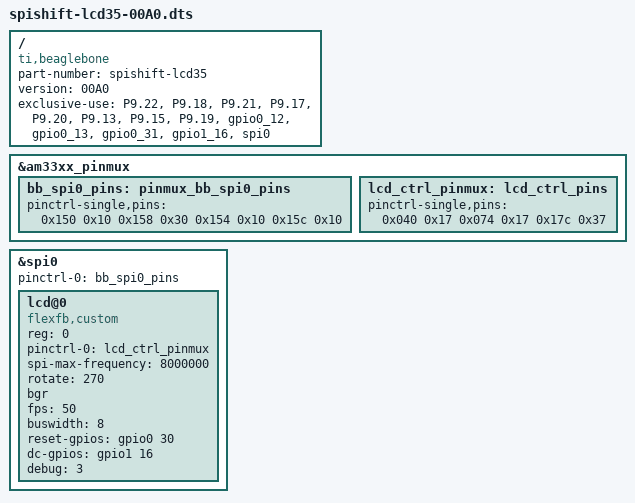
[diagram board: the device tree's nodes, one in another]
/*
 * Based on NEOSEC-TINYLCD35-00A0.dts, which is:
 * Copyright (C) 2014 Noralf Tronnes
 *
 * spishift-lcd35 : 4 wire SPI->shift register 3.5" display, on SPI0
 *
 * This program is free software; you can redistribute it and/or modify
 * it under the terms of the GNU General Public License version 2 as
 * published by the Free Software Foundation.
 */

/dts-v1/;
/plugin/;
/ {
	compatible = "ti,beaglebone", "ti,beaglebone-black";

	/* identification */
	part-number = "spishift-lcd35";
	version = "00A0";

	/* state the resources this cape uses */
	exclusive-use =
		/* the pin header uses */
		"P9.22",	/* spi0_sclk */
		"P9.18",	/* spi0_d1 MISO note we are using ti,pindir-d0-out-d1-in = <1> in spi0 */
		"P9.21",	/* spi0_d0 MOSI note we are using ti,pindir-d0-out-d1-in = <1> in spi0 */
		"P9.17",	/* spi0_cs0 */
		"P9.20",	/* gpio0_12 (12) second cs for touch */
		"P9.13",	/* gpio0_31 (31) display reset */
		"P9.15",	/* gpio1_16 (48) display dc data/command */
		"P9.19",	/* gpio0_13 (13) touch irq */
		/* the hardware IP uses */
		"gpio0_12",
		"gpio0_13",
		"gpio0_31",
		"gpio1_16",
		"spi0";

	fragment@0 {
		target = <&am33xx_pinmux>;
		__overlay__ {
			bb_spi0_pins: pinmux_bb_spi0_pins {
				pinctrl-single,pins = <
				        0x150 0x10      /* (PIN_OUTPUT_PULLUP | MUX_MODE0) spi0_sclk */
					0x158 0x30      /* (PIN_INPUT_PULLUP | MUX_MODE0)  spi0_d1 (input) */
					0x154 0x10      /* (PIN_OUTPUT_PULLUP | MUX_MODE0) spi0_d0 (output) */
					0x15c 0x10      /* (PIN_OUTPUT_PULLUP | MUX_MODE0) spi0_cs0 */
				>;
			};

			lcd_ctrl_pinmux: lcd_ctrl_pins {
				pinctrl-single,pins = <
					0x040 0x17	/* P9.15 gpio1_16  OUTPUT_PULLUP | MODE7 (DSP_DC) */
					0x074 0x17	/* P9.13 gpio0_30  OUTPUT_PULLUP | MODE7 (DSP_RESET) */
					0x17c 0x37	/* P9.19 gpio0_13  INPUT_PULLUP  | MODE7 (TP_IRQ) */
				>;
			};
		};
	};

	fragment@1 {
		target = <&spi0>;
		__overlay__ {
			status = "okay";
			pinctrl-names = "default";
			pinctrl-0 = <&bb_spi0_pins>;

			#address-cells = <1>;
			#size-cells = <0>;

			lcd@0{
				compatible = "flexfb,custom";
				reg = <0>;

				pinctrl-names = "default";
				pinctrl-0 = <&lcd_ctrl_pinmux>;

//				spi-max-frequency = <48000000>;
				spi-max-frequency = <8000000>;
				rotate = <270>;
				bgr;
				fps = <50>;
				buswidth = <8>;
				reset-gpios = <&gpio0 30 0>;
				dc-gpios = <&gpio1 16 0>;

				debug = <3>;
			};
		};
	};

	// fragment@2 {
	// 	target = <&epwmss1>;
	// 	__overlay__ {
	// 		status = "okay";
	// 	};
	// };

	// fragment@3 {
	// 	target = <&ehrpwm1>;
	// 	__overlay__ {
	// 		status = "okay";
	// 	};
	// };

	// fragment@4 {
	// 	target = <&ocp>;
	// 	__overlay__ {
	// 		backlight {
	// 			compatible = "pwm-backlight";
	// 			pinctrl-names = "default";
	// 			pinctrl-0 = <&pwm_bl_pins>;
	// 			status = "okay";

	// 			pwms = <&ehrpwm1 0 500000 0>;
	// 			pwm-names = "backlight";
	// 			brightness-levels = <0 4 8 16 32 64 128 255>;
	// 			default-brightness-level = <7>; /* index to the array above */
	// 		};
	// 	};
	// };
};
